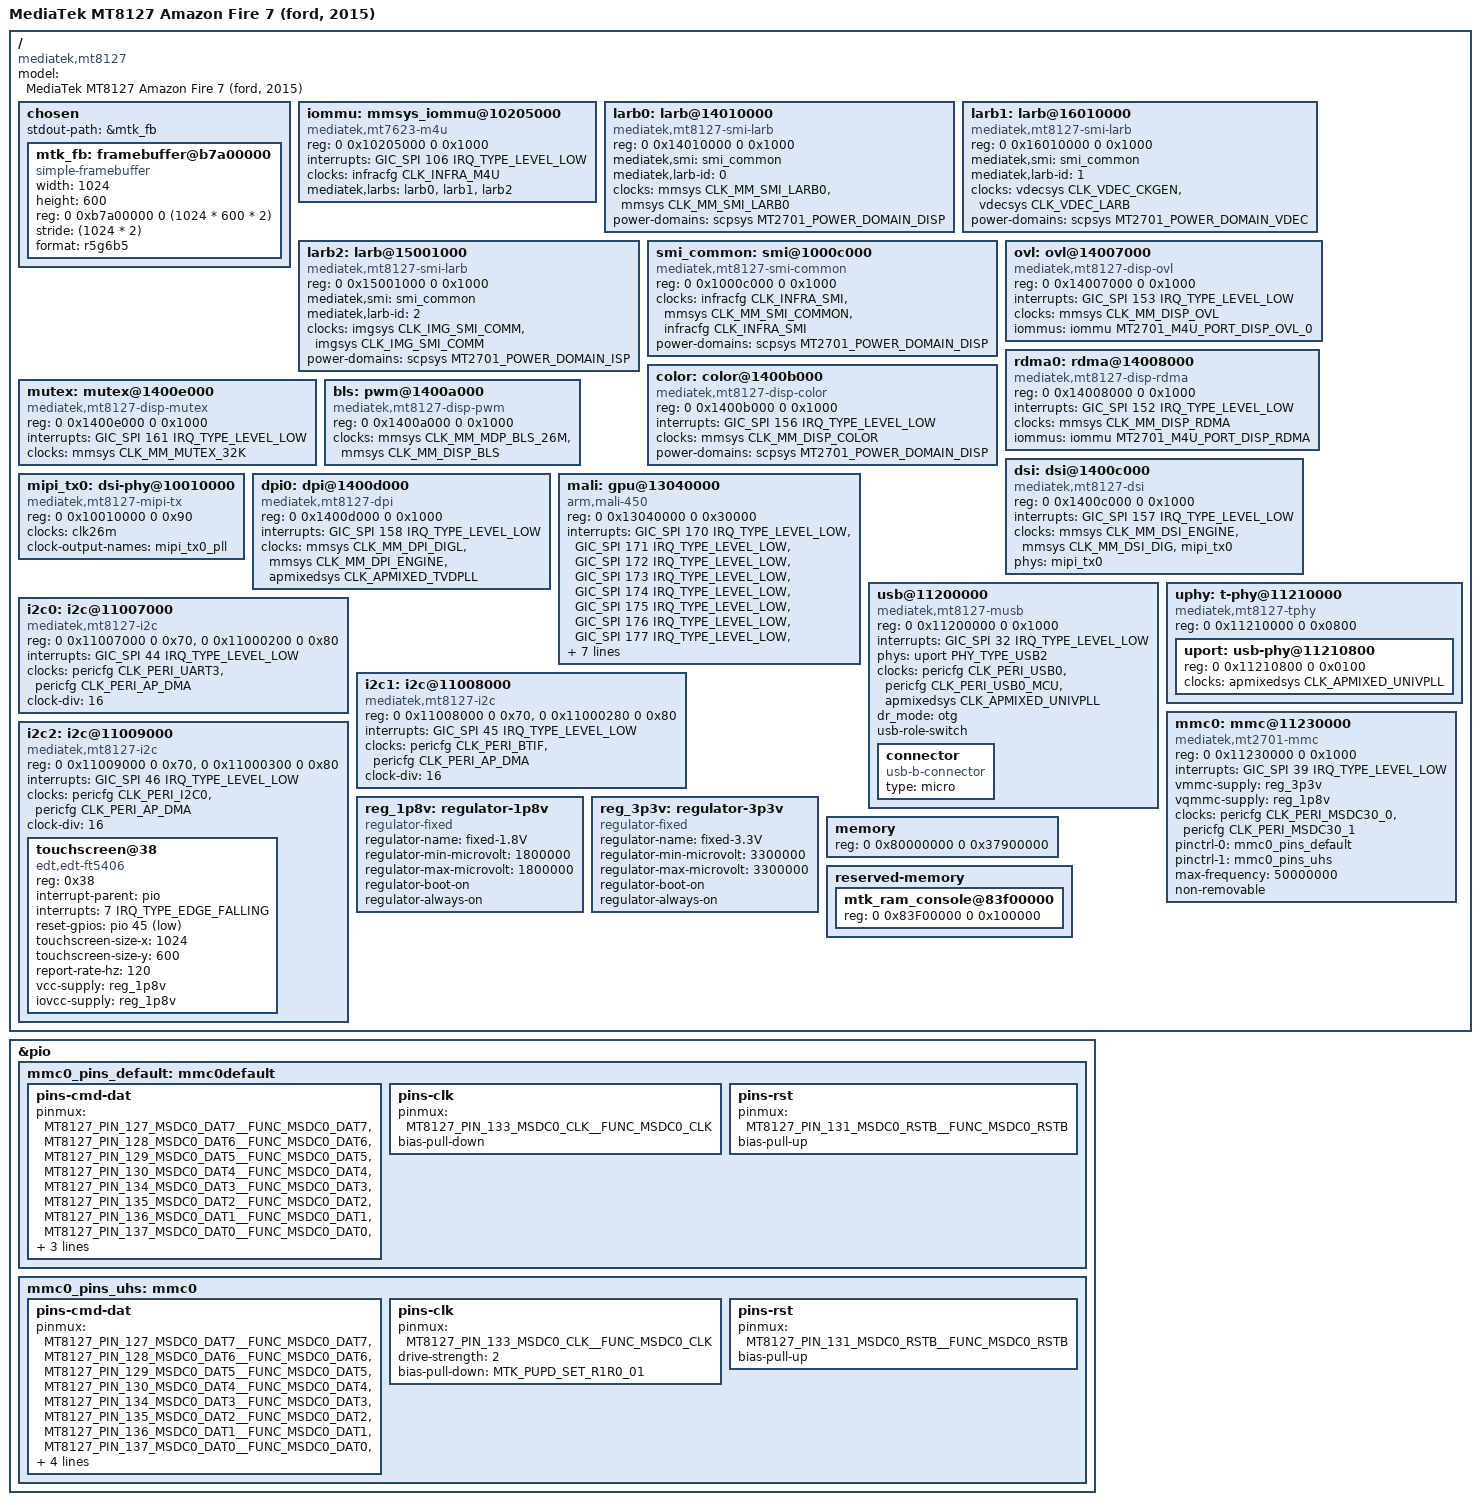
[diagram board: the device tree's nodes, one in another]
// SPDX-License-Identifier: GPL-2.0
/*
 * Copyright (c) 2014 MediaTek Inc.
 * Author: Joe.C <yingjoe.chen@mediatek.com>
 *
 */

/dts-v1/;
#include "mt8127.dtsi"
#include <dt-bindings/phy/phy.h>
#include "mt8127-pinfunc.h"
#include <dt-bindings/memory/mt2701-larb-port.h>
#include <dt-bindings/gpio/gpio.h>
#include <dt-bindings/input/input.h>

/ {
	model = "MediaTek MT8127 Amazon Fire 7 (ford, 2015)";
	compatible = "mediatek,mt8127";

	chosen {
		stdout-path = &mtk_fb;
		#address-cells = <2>;
		#size-cells = <2>;
		ranges;

		mtk_fb: framebuffer@b7a00000 {
			compatible = "simple-framebuffer";
			width = <1024>;
			height = <600>;
			reg = <0 0xb7a00000 0 (1024 * 600 * 2)>;
			stride = <(1024 * 2)>;
			format = "r5g6b5";
		};
	};

	iommu: mmsys_iommu@10205000 {
		compatible = "mediatek,mt7623-m4u",
		"mediatek,mt2701-m4u";
		reg = <0 0x10205000 0 0x1000>;
		interrupts = <GIC_SPI 106 IRQ_TYPE_LEVEL_LOW>;
		clocks = <&infracfg CLK_INFRA_M4U>;
		clock-names = "bclk";
		mediatek,larbs = <&larb0 &larb1 &larb2>;
		#iommu-cells = <1>;
	};

	larb0: larb@14010000 {
		compatible = "mediatek,mt8127-smi-larb",
		"mediatek,mt2701-smi-larb";
		reg = <0 0x14010000 0 0x1000>;
		mediatek,smi = <&smi_common>;
		mediatek,larb-id = <0>;
		clocks = <&mmsys CLK_MM_SMI_LARB0>,
		<&mmsys CLK_MM_SMI_LARB0>;
		clock-names = "apb", "smi";
		power-domains = <&scpsys MT2701_POWER_DOMAIN_DISP>;
	};

	larb1: larb@16010000 {
		compatible = "mediatek,mt8127-smi-larb",
		"mediatek,mt2701-smi-larb";
		reg = <0 0x16010000 0 0x1000>;
		mediatek,smi = <&smi_common>;
		mediatek,larb-id = <1>;
		clocks = <&vdecsys CLK_VDEC_CKGEN>,
		<&vdecsys CLK_VDEC_LARB>;
		clock-names = "apb", "smi";
		power-domains = <&scpsys MT2701_POWER_DOMAIN_VDEC>;
	};

	larb2: larb@15001000 {
		compatible = "mediatek,mt8127-smi-larb",
		"mediatek,mt2701-smi-larb";
		reg = <0 0x15001000 0 0x1000>;
		mediatek,smi = <&smi_common>;
		mediatek,larb-id = <2>;
		clocks = <&imgsys CLK_IMG_SMI_COMM>,
		<&imgsys CLK_IMG_SMI_COMM>;
		clock-names = "apb", "smi";
		power-domains = <&scpsys MT2701_POWER_DOMAIN_ISP>;
	};

	smi_common: smi@1000c000 {
		compatible = "mediatek,mt8127-smi-common",
		"mediatek,mt2701-smi-common";
		reg = <0 0x1000c000 0 0x1000>;
		clocks = <&infracfg CLK_INFRA_SMI>,
		<&mmsys CLK_MM_SMI_COMMON>,
		<&infracfg CLK_INFRA_SMI>;
		clock-names = "apb", "smi", "async";
		power-domains = <&scpsys MT2701_POWER_DOMAIN_DISP>;
	};

	ovl: ovl@14007000 {
		compatible = "mediatek,mt8127-disp-ovl",
		"mediatek,mt2701-disp-ovl";
		reg = <0 0x14007000 0 0x1000>;
		interrupts = <GIC_SPI 153 IRQ_TYPE_LEVEL_LOW>;
		clocks = <&mmsys CLK_MM_DISP_OVL>;
		iommus = <&iommu MT2701_M4U_PORT_DISP_OVL_0>;
	};

	rdma0: rdma@14008000 {
		compatible = "mediatek,mt8127-disp-rdma",
		"mediatek,mt2701-disp-rdma";
		reg = <0 0x14008000 0 0x1000>;
		interrupts = <GIC_SPI 152 IRQ_TYPE_LEVEL_LOW>;
		clocks = <&mmsys CLK_MM_DISP_RDMA>;
		iommus = <&iommu MT2701_M4U_PORT_DISP_RDMA>;
	};

	color: color@1400b000 {
		compatible = "mediatek,mt8127-disp-color",
		"mediatek,mt2701-disp-color";
		reg = <0 0x1400b000 0 0x1000>;
		interrupts = <GIC_SPI 156 IRQ_TYPE_LEVEL_LOW>;
		clocks = <&mmsys CLK_MM_DISP_COLOR>;
		power-domains = <&scpsys MT2701_POWER_DOMAIN_DISP>;
	};

	mutex: mutex@1400e000 {
		compatible = "mediatek,mt8127-disp-mutex",
		"mediatek,mt2701-disp-mutex";
		reg = <0 0x1400e000 0 0x1000>;
		interrupts = <GIC_SPI 161 IRQ_TYPE_LEVEL_LOW>;
		clocks = <&mmsys CLK_MM_MUTEX_32K>;
	};

	bls: pwm@1400a000 {
		compatible = "mediatek,mt8127-disp-pwm",
		"mediatek,mt2701-disp-pwm";
		reg = <0 0x1400a000 0 0x1000>;
		#pwm-cells = <2>;
		clocks = <&mmsys CLK_MM_MDP_BLS_26M>,
		<&mmsys CLK_MM_DISP_BLS>;
		clock-names = "main", "mm";
	};

	dsi: dsi@1400c000 {
		compatible = "mediatek,mt8127-dsi",
		"mediatek,mt2701-dsi";
		reg = <0 0x1400c000 0 0x1000>;
		interrupts = <GIC_SPI 157 IRQ_TYPE_LEVEL_LOW>;
		clocks = <&mmsys CLK_MM_DSI_ENGINE>,
		<&mmsys CLK_MM_DSI_DIG>,
		<&mipi_tx0>;
		clock-names = "engine", "digital", "hs";
		phys = <&mipi_tx0>;
		phy-names = "dphy";
	};

	mipi_tx0: dsi-phy@10010000 {
		compatible = "mediatek,mt8127-mipi-tx",
		"mediatek,mt2701-mipi-tx";
		reg = <0 0x10010000 0 0x90>;
		clocks = <&clk26m>;
		clock-output-names = "mipi_tx0_pll";
		#clock-cells = <0>;
		#phy-cells = <0>;
	};

	dpi0: dpi@1400d000 {
		compatible = "mediatek,mt8127-dpi",
		"mediatek,mt2701-dpi";
		reg = <0 0x1400d000 0 0x1000>;
		interrupts = <GIC_SPI 158 IRQ_TYPE_LEVEL_LOW>;
		clocks = <&mmsys CLK_MM_DPI_DIGL>,
		<&mmsys CLK_MM_DPI_ENGINE>,
		<&apmixedsys CLK_APMIXED_TVDPLL>;
		clock-names = "pixel", "engine", "pll";
	};

	mali: gpu@13040000 {
		compatible = "arm,mali-450";
		reg = <0 0x13040000 0 0x30000>;
		interrupts = <GIC_SPI 170 IRQ_TYPE_LEVEL_LOW>,
		<GIC_SPI 171 IRQ_TYPE_LEVEL_LOW>,
		<GIC_SPI 172 IRQ_TYPE_LEVEL_LOW>,
		<GIC_SPI 173 IRQ_TYPE_LEVEL_LOW>,
		<GIC_SPI 174 IRQ_TYPE_LEVEL_LOW>,
		<GIC_SPI 175 IRQ_TYPE_LEVEL_LOW>,
		<GIC_SPI 176 IRQ_TYPE_LEVEL_LOW>,
		<GIC_SPI 177 IRQ_TYPE_LEVEL_LOW>,
		<GIC_SPI 178 IRQ_TYPE_LEVEL_LOW>,
		<GIC_SPI 179 IRQ_TYPE_LEVEL_LOW>,
		<GIC_SPI 180 IRQ_TYPE_LEVEL_LOW>;
		interrupt-names = "gp",
		"gpmmu",
		"pp0",
		"ppmmu0",
		"pp1",
		"ppmmu1",
		"pp2",
		"ppmmu2",
		"pp3",
		"ppmmu3",
		"pp";
		clocks = <&topckgen CLK_TOP_MMPLL>, <&g3dsys CLK_G3DSYS_CORE>;
		clock-names = "bus", "core";
		power-domains = <&scpsys MT2701_POWER_DOMAIN_MFG>;
		resets = <&g3dsys MT2701_G3DSYS_CORE_RST>;
	};

	usb@11200000 {
		compatible = "mediatek,mt8127-musb", "mediatek,mtk-musb";
		reg = <0 0x11200000 0 0x1000>;
		interrupts = <GIC_SPI 32 IRQ_TYPE_LEVEL_LOW>;
		interrupt-names = "mc";
		phys = <&uport PHY_TYPE_USB2>;
		clocks = <&pericfg CLK_PERI_USB0>,
			 <&pericfg CLK_PERI_USB0_MCU>,
			 <&apmixedsys CLK_APMIXED_UNIVPLL>;
		clock-names = "main","mcu","univpll";
		dr_mode = "otg";
		usb-role-switch;

		connector {
			compatible = "usb-b-connector";
			type = "micro";
		};
	};

	uphy: t-phy@11210000 {
		compatible = "mediatek,mt8127-tphy",
		"mediatek,generic-tphy-v1";
		reg = <0 0x11210000 0 0x0800>;
		#address-cells = <2>;
		#size-cells = <2>;
		ranges;

		uport: usb-phy@11210800 {
			reg = <0 0x11210800 0 0x0100>;
			clocks = <&apmixedsys CLK_APMIXED_UNIVPLL>;
			clock-names = "ref";
			#phy-cells = <1>;
		};
	};

	i2c0: i2c@11007000 {
		compatible = "mediatek,mt8127-i2c";
		reg = <0 0x11007000 0 0x70>, <0 0x11000200 0 0x80>;
		interrupts = <GIC_SPI 44 IRQ_TYPE_LEVEL_LOW>;
		clocks = <&pericfg CLK_PERI_UART3>, <&pericfg CLK_PERI_AP_DMA>;
		clock-names = "main", "dma";
		clock-div = <16>;

		#address-cells = <1>;
		#size-cells = <0>;
	};

	i2c1: i2c@11008000 {
		compatible = "mediatek,mt8127-i2c";
		reg = <0 0x11008000 0 0x70>, <0 0x11000280 0 0x80>;
		interrupts = <GIC_SPI 45 IRQ_TYPE_LEVEL_LOW>;
		clocks = <&pericfg CLK_PERI_BTIF>, <&pericfg CLK_PERI_AP_DMA>;
		clock-names = "main", "dma";
		clock-div = <16>;

		#address-cells = <1>;
		#size-cells = <0>;
	};

	i2c2: i2c@11009000 {
		compatible = "mediatek,mt8127-i2c";
		reg = <0 0x11009000 0 0x70>, <0 0x11000300 0 0x80>;
		interrupts = <GIC_SPI 46 IRQ_TYPE_LEVEL_LOW>;
		clocks = <&pericfg CLK_PERI_I2C0>, <&pericfg CLK_PERI_AP_DMA>;
		clock-names = "main", "dma";
		clock-div = <16>;

		#address-cells = <1>;
		#size-cells = <0>;

		touchscreen@38 {
			compatible = "edt,edt-ft5406";
			reg = <0x38>;

			interrupt-parent = <&pio>;
			interrupts = <7 IRQ_TYPE_EDGE_FALLING>;

			reset-gpios = <&pio 45 GPIO_ACTIVE_LOW>;

			touchscreen-size-x = <1024>;
			touchscreen-size-y = <600>;

			report-rate-hz = <120>;

			vcc-supply = <&reg_1p8v>;
			iovcc-supply = <&reg_1p8v>;
		};
	};

	mmc0: mmc@11230000 {
		compatible = "mediatek,mt2701-mmc";
		reg = <0 0x11230000 0 0x1000>;
		interrupts = <GIC_SPI 39 IRQ_TYPE_LEVEL_LOW>;
		vmmc-supply = <&reg_3p3v>;
		vqmmc-supply = <&reg_1p8v>;
		clocks = <&pericfg CLK_PERI_MSDC30_0>,
		<&pericfg CLK_PERI_MSDC30_1>;
		clock-names = "source", "hclk";
		pinctrl-names = "default", "state_uhs";
		pinctrl-0 = <&mmc0_pins_default>;
		pinctrl-1 = <&mmc0_pins_uhs>;
		max-frequency = <50000000>;
		non-removable;
	};

	reg_1p8v: regulator-1p8v {
		compatible = "regulator-fixed";
		regulator-name = "fixed-1.8V";
		regulator-min-microvolt = <1800000>;
		regulator-max-microvolt = <1800000>;
		regulator-boot-on;
		regulator-always-on;
	};

	reg_3p3v: regulator-3p3v {
		compatible = "regulator-fixed";
		regulator-name = "fixed-3.3V";
		regulator-min-microvolt = <3300000>;
		regulator-max-microvolt = <3300000>;
		regulator-boot-on;
		regulator-always-on;
	};

	memory {
		device_type = "memory";
		reg = <0 0x80000000 0 0x37900000>;
	};

	reserved-memory {
		#address-cells = <2>;
		#size-cells = <2>;
		ranges;

		mtk_ram_console@83f00000 {
			reg = <0 0x83F00000 0 0x100000>;
		};
	};
};

&pio {
	mmc0_pins_default: mmc0default {
		pins-cmd-dat {
			pinmux = <MT8127_PIN_127_MSDC0_DAT7__FUNC_MSDC0_DAT7>,
			<MT8127_PIN_128_MSDC0_DAT6__FUNC_MSDC0_DAT6>,
			<MT8127_PIN_129_MSDC0_DAT5__FUNC_MSDC0_DAT5>,
			<MT8127_PIN_130_MSDC0_DAT4__FUNC_MSDC0_DAT4>,
			<MT8127_PIN_134_MSDC0_DAT3__FUNC_MSDC0_DAT3>,
			<MT8127_PIN_135_MSDC0_DAT2__FUNC_MSDC0_DAT2>,
			<MT8127_PIN_136_MSDC0_DAT1__FUNC_MSDC0_DAT1>,
			<MT8127_PIN_137_MSDC0_DAT0__FUNC_MSDC0_DAT0>,
			<MT8127_PIN_132_MSDC0_CMD__FUNC_MSDC0_CMD>;
			input-enable;
			bias-pull-up;
		};

		pins-clk {
			pinmux = <MT8127_PIN_133_MSDC0_CLK__FUNC_MSDC0_CLK>;
			bias-pull-down;
		};

		pins-rst {
			pinmux = <MT8127_PIN_131_MSDC0_RSTB__FUNC_MSDC0_RSTB>;
			bias-pull-up;
		};
	};

	mmc0_pins_uhs: mmc0 {
		pins-cmd-dat {
			pinmux = <MT8127_PIN_127_MSDC0_DAT7__FUNC_MSDC0_DAT7>,
			<MT8127_PIN_128_MSDC0_DAT6__FUNC_MSDC0_DAT6>,
			<MT8127_PIN_129_MSDC0_DAT5__FUNC_MSDC0_DAT5>,
			<MT8127_PIN_130_MSDC0_DAT4__FUNC_MSDC0_DAT4>,
			<MT8127_PIN_134_MSDC0_DAT3__FUNC_MSDC0_DAT3>,
			<MT8127_PIN_135_MSDC0_DAT2__FUNC_MSDC0_DAT2>,
			<MT8127_PIN_136_MSDC0_DAT1__FUNC_MSDC0_DAT1>,
			<MT8127_PIN_137_MSDC0_DAT0__FUNC_MSDC0_DAT0>,
			<MT8127_PIN_132_MSDC0_CMD__FUNC_MSDC0_CMD>;
			input-enable;
			drive-strength = <2>;
			bias-pull-up = <MTK_PUPD_SET_R1R0_01>;
		};

		pins-clk {
			pinmux = <MT8127_PIN_133_MSDC0_CLK__FUNC_MSDC0_CLK>;
			drive-strength = <2>;
			bias-pull-down = <MTK_PUPD_SET_R1R0_01>;
		};

		pins-rst {
			pinmux = <MT8127_PIN_131_MSDC0_RSTB__FUNC_MSDC0_RSTB>;
			bias-pull-up;
		};
	};
};
